# CY8C5888LTI_LP097 register map
File version: 0.1
CY8C58LP
Registers are 8-bit, read-write, no defined reset value unless marked. A register's access mark holds for its fields unless they carry their own. Offsets are from the block's base; lines under a group give offsets from that group; [hi:lo] are bit positions; {n}, {i} and the like mark numbered series; 'fields as' and 'values as' point back to an identical list; <NAME> marks a mode.

## Memory map
0x00000000 SDI12_UART — UART
0x40006575 SDI12_control_reg

## SDI12_control_reg
Base 0x40006575
0x00 SDI12_control_reg_CONTROL_REG

## SDI12_UART — UART
Base 0x00000000
0x40006447 TX_SDI12_UART_TX_DATA — TX Data Register
0x40006526 RX_SDI12_UART_RX_ADDRESS1 — RX Address1 Register
0x40006536 RX_SDI12_UART_RX_ADDRESS2 — RX Address2 Register
0x40006546 RX_SDI12_UART_RX_DATA — RX Data Register
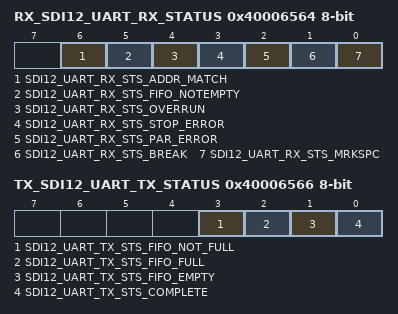
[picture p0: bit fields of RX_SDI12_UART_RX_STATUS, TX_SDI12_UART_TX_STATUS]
0x40006564 RX_SDI12_UART_RX_STATUS — RX status register
  [6] SDI12_UART_RX_STS_ADDR_MATCH ro, [5] SDI12_UART_RX_STS_FIFO_NOTEMPTY ro, [4] SDI12_UART_RX_STS_OVERRUN ro, [3] SDI12_UART_RX_STS_STOP_ERROR ro, [2] SDI12_UART_RX_STS_PAR_ERROR ro, [1] SDI12_UART_RX_STS_BREAK ro, [0] SDI12_UART_RX_STS_MRKSPC ro
0x40006566 TX_SDI12_UART_TX_STATUS — TX status register
  [3] SDI12_UART_TX_STS_FIFO_NOT_FULL ro, [2] SDI12_UART_TX_STS_FIFO_FULL ro, [1] SDI12_UART_TX_STS_FIFO_EMPTY ro, [0] SDI12_UART_TX_STS_COMPLETE ro
